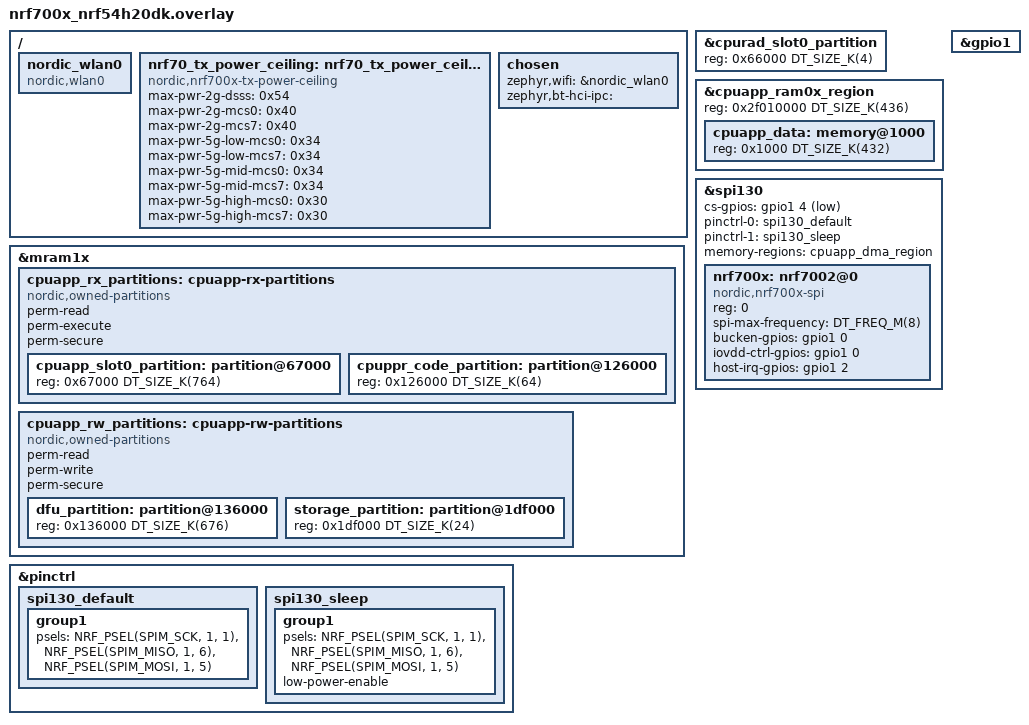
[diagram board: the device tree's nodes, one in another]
/* Copyright (c) 2023 Nordic Semiconductor ASA
 *
 * SPDX-License-Identifier: LicenseRef-Nordic-5-Clause
 */
#include <freq.h>

/ {
	nordic_wlan0: nordic_wlan0 {
		compatible = "nordic,wlan0";
		status = "okay";
	};

	nrf70_tx_power_ceiling: nrf70_tx_power_ceiling_node {
		status = "okay";
		compatible = "nordic,nrf700x-tx-power-ceiling";
		max-pwr-2g-dsss = <0x54>;
		max-pwr-2g-mcs0 = <0x40>;
		max-pwr-2g-mcs7 = <0x40>;
		max-pwr-5g-low-mcs0 = <0x34>;
		max-pwr-5g-low-mcs7 = <0x34>;
		max-pwr-5g-mid-mcs0 = <0x34>;
		max-pwr-5g-mid-mcs7 = <0x34>;
		max-pwr-5g-high-mcs0 = <0x30>;
		max-pwr-5g-high-mcs7 = <0x30>;
	};

	chosen {
		zephyr,wifi = &nordic_wlan0;
		zephyr,bt-hci-ipc = "";
	};

	cpurad_ram0x_region: memory@2f07d000 {
		compatible = "nordic,owned-memory";
		reg = <0x2f07d000 DT_SIZE_K(4)>;
		status = "disabled";
		perm-read;
		perm-write;
		perm-secure;
		#address-cells = <1>;
		#size-cells = <1>;
		ranges = <0x0 0x2f07d000 0x1000>;

		cpusec_cpurad_ipc_shm: memory@0 {
			reg = <0x0 DT_SIZE_K(2)>;
		};

		cpurad_cpusec_ipc_shm: memory@800 {
			reg = <0x800 DT_SIZE_K(2)>;
		};
	};
};

/* Wi-Fi needs more flash, so, minimize Radio memory to make room for Wi-Fi */
/delete-node/ &cpuapp_rx_partitions;
/delete-node/ &cpuapp_rw_partitions;

/* For MPC, min. granularity is 4K*/
&cpurad_slot0_partition {
	reg = <0x66000 DT_SIZE_K(4)>;
};

&mram1x {
	cpuapp_rx_partitions: cpuapp-rx-partitions {
		compatible = "nordic,owned-partitions", "fixed-partitions";
		status = "okay";
		perm-read;
		perm-execute;
		perm-secure;
		#address-cells = <1>;
		#size-cells = <1>;

		cpuapp_slot0_partition: partition@67000 {
			reg = <0x67000 DT_SIZE_K(764)>;
		};

		cpuppr_code_partition: partition@126000 {
			reg = <0x126000 DT_SIZE_K(64)>;
		};
	};
	cpuapp_rw_partitions: cpuapp-rw-partitions {
		compatible = "nordic,owned-partitions", "fixed-partitions";
		status = "okay";
		perm-read;
		perm-write;
		perm-secure;
		#address-cells = <1>;
		#size-cells = <1>;

		dfu_partition: partition@136000 {
			reg = < 0x136000 DT_SIZE_K(676) >;
		};

		storage_partition: partition@1df000 {
			reg = < 0x1df000 DT_SIZE_K(24) >;
		};
	};
};

/delete-node/ &cpurad_ram0x_region;
&cpuapp_ram0x_region{
	status = "okay";
	reg = <0x2f010000 DT_SIZE_K(436)>;
	ranges = <0x0 0x2f010000 0x6e000>;
	cpuapp_data: memory@1000 {
		reg = <0x1000 DT_SIZE_K(432)>;
	};
};


&pinctrl {
	spi130_default: spi130_default {
		group1 {
			/* SCK has to be 0..3 and other signals can't use these pins */
			psels = <NRF_PSEL(SPIM_SCK, 1, 1)>,
				<NRF_PSEL(SPIM_MISO, 1, 6)>,
				<NRF_PSEL(SPIM_MOSI, 1, 5)>;
		};
	};

	spi130_sleep: spi130_sleep {
		group1 {
			psels = <NRF_PSEL(SPIM_SCK, 1, 1)>,
				<NRF_PSEL(SPIM_MISO, 1, 6)>,
				<NRF_PSEL(SPIM_MOSI, 1, 5)>;
			low-power-enable;
		};
	};
};

&spi130 {
	status = "okay";
	cs-gpios = <&gpio1 4 GPIO_ACTIVE_LOW>;

	pinctrl-0 = <&spi130_default>;
	pinctrl-1 = <&spi130_sleep>;
	pinctrl-names = "default", "sleep";
	memory-regions = <&cpuapp_dma_region>;
	nrf700x: nrf7002@0 {
		compatible = "nordic,nrf700x-spi";
		status = "okay";
		reg = <0>;
		spi-max-frequency = <DT_FREQ_M(8)>;
		bucken-gpios = <&gpio1 0 (GPIO_ACTIVE_HIGH | GPIO_PULL_DOWN)>;
		iovdd-ctrl-gpios = <&gpio1 0 (GPIO_ACTIVE_HIGH | GPIO_PULL_DOWN)>;
		host-irq-gpios = <&gpio1 2 GPIO_ACTIVE_HIGH>;
	};
};

&gpio1 {
	status = "okay";
};
